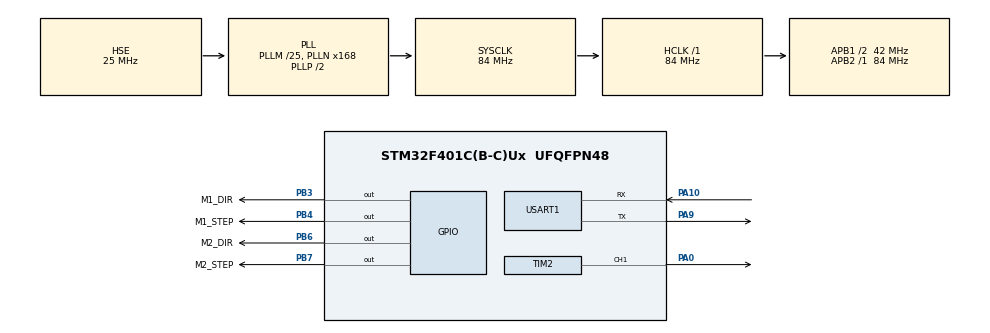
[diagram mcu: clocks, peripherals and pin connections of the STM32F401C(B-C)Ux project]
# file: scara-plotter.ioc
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Mcu.Family=STM32F4
Mcu.Name=STM32F401C(B-C)Ux
Mcu.Package=UFQFPN48
NVIC.PriorityGroup=NVIC_PRIORITYGROUP_4
NVIC.TIM2_IRQn=true\:0\:0\:false\:false\:true\:true\:true
NVIC.USART1_IRQn=true\:0\:0\:false\:false\:true\:true\:true
PA0-WKUP.Signal=S_TIM2_CH1_ETR
PA10.Mode=Asynchronous
PA10.Signal=USART1_RX
PA13.Mode=Serial_Wire
PA13.Signal=SYS_JTMS-SWDIO
PA14.Mode=Serial_Wire
PA14.Signal=SYS_JTCK-SWCLK
PA9.Mode=Asynchronous
PA9.Signal=USART1_TX
PB3.GPIO_Label=M1_DIR
PB3.Signal=GPIO_Output
PB4.GPIO_Label=M1_STEP
PB4.Signal=GPIO_Output
PB6.GPIO_Label=M2_DIR
PB6.Signal=GPIO_Output
PB7.GPIO_Label=M2_STEP
PB7.Signal=GPIO_Output
PH0\ -\ OSC_IN.Mode=HSE-External-Oscillator
PH0\ -\ OSC_IN.Signal=RCC_OSC_IN
PH1\ -\ OSC_OUT.Mode=HSE-External-Oscillator
PH1\ -\ OSC_OUT.Signal=RCC_OSC_OUT
ProjectManager.HeapSize=0x200
ProjectManager.StackSize=0x400
ProjectManager.TargetToolchain=STM32CubeIDE
RCC.48MHZClocksFreq_Value=42000000
RCC.AHBFreq_Value=84000000
RCC.APB1CLKDivider=RCC_HCLK_DIV2
RCC.APB1Freq_Value=42000000
RCC.APB1TimFreq_Value=84000000
RCC.APB2Freq_Value=84000000
RCC.APB2TimFreq_Value=84000000
RCC.CortexFreq_Value=84000000
RCC.HCLKFreq_Value=84000000
RCC.HSE_VALUE=25000000
RCC.HSI_VALUE=16000000
RCC.LSE_VALUE=32768
RCC.PLLM=25
RCC.PLLN=168
RCC.PLLSourceVirtual=RCC_PLLSOURCE_HSE
RCC.SYSCLKFreq_VALUE=84000000
RCC.SYSCLKSource=RCC_SYSCLKSOURCE_PLLCLK
RCC.VCOOutputFreq_Value=168000000
SH.S_TIM2_CH1_ETR.0=TIM2_CH1,PWM Generation1 CH1
TIM2.Channel-PWM\ Generation1\ CH1=TIM_CHANNEL_1
TIM2.Period=59999
TIM2.Prescaler=27
TIM3.Prescaler=83
USART1.VirtualMode=VM_ASYNC
VP_TIM2_VS_ClockSourceINT.Mode=Internal
VP_TIM3_VS_ClockSourceINT.Mode=Internal
board=custom

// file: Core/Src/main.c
/* USER CODE BEGIN Header */
/**
  ******************************************************************************
  * @file           : main.c
  * @brief          : Main program body
  ******************************************************************************
  * @attention
  *
  * <h2><center>&copy; Copyright (c) 2021 STMicroelectronics.
  * All rights reserved.</center></h2>
  *
  * This software component is licensed by ST under BSD 3-Clause license,
  * the "License"; You may not use this file except in compliance with the
  * License. You may obtain a copy of the License at:
  *                        opensource.org/licenses/BSD-3-Clause
  *
  ******************************************************************************
  */
/* USER CODE END Header */
#include "main.h"

TIM_HandleTypeDef htim2;
TIM_HandleTypeDef htim3;

UART_HandleTypeDef huart1;

/* USER CODE BEGIN PV */
TIM_HandleTypeDef *htim = &htim2;
TIM_HandleTypeDef *htim_ms = &htim3;

/* USER CODE END PV */

void SystemClock_Config(void);
static void MX_GPIO_Init(void);
static void MX_TIM2_Init(void);
static void MX_TIM3_Init(void);
static void MX_USART1_UART_Init(void);

int main(void)
{
  /* USER CODE BEGIN 1 */
  uint8_t uart_buffer[40] = {0};

  /* USER CODE END 1 */

  /* MCU Configuration--------------------------------------------------------*/

  /* Reset of all peripherals, Initializes the Flash interface and the Systick. */
  HAL_Init();

  /* Configure the system clock */
  SystemClock_Config();

  /* Initialize all configured peripherals */
  MX_GPIO_Init();
  MX_TIM2_Init();
  MX_TIM3_Init();
  MX_USART1_UART_Init();
  /* USER CODE BEGIN 2 */

  HAL_TIM_PWM_Start(&htim2, TIM_CHANNEL_1);
  HAL_TIM_Base_Start(&htim3);

  lift();
  go_to(0, 200);

  /* USER CODE END 2 */

  /* Infinite loop */
  /* USER CODE BEGIN WHILE */
  while (1)
  {

    HAL_UART_Receive (&huart1, uart_buffer, sizeof(uart_buffer), HAL_MAX_DELAY);

    //procesar
    parse_line(uart_buffer, sizeof(uart_buffer));

    HAL_UART_Transmit(&huart1, "OK\n", 3, HAL_MAX_DELAY);

    //lift();

    //HAL_Delay(1000);

    //go_to(0, 230);
    //put_down();

    //HAL_Delay(1000);

    //go_to(0, 270);

    /*draw_line(-75.0, 250.0, 175.0, 250.0, true);
    draw_line(175.0, 250.0, 175.0, 380.0, true);
    draw_line(175.0, 380.0, -75.0, 380.0, true);
    draw_line(-75.0, 380.0, -75.0, 250.0, false);

    draw_line(-50.0, 275.0, 150.0, 275.0, true);
    draw_line(150.0, 275.0, 150.0, 355.0, true);
    draw_line(150.0, 355.0, -50.0, 355.0, true);
    draw_line(-50.0, 355.0, -50.0, 275.0, false);

    draw_line(-25.0, 300.0, 125.0, 300.0, true);
    draw_line(125.0, 300.0, 125.0, 320.0, true);
    draw_line(125.0, 320.0, -25.0, 320.0, true);
    draw_line(-25.0, 320.0, -25.0, 300.0, false);

    draw_circle(50.0, 315.0, 60.0);
    draw_circle(50.0, 315.0, 50.0);
    draw_circle(50.0, 315.0, 40.0);

    HAL_Delay(30000);*/

    /* USER CODE END WHILE */

  }
}

void SystemClock_Config(void)
{
  RCC_OscInitTypeDef RCC_OscInitStruct = {0};
  RCC_ClkInitTypeDef RCC_ClkInitStruct = {0};

  /** Configure the main internal regulator output voltage
  */
  __HAL_RCC_PWR_CLK_ENABLE();
  __HAL_PWR_VOLTAGESCALING_CONFIG(PWR_REGULATOR_VOLTAGE_SCALE2);
  /** Initializes the RCC Oscillators according to the specified parameters
  * in the RCC_OscInitTypeDef structure.
  */
  RCC_OscInitStruct.OscillatorType = RCC_OSCILLATORTYPE_HSE;
  RCC_OscInitStruct.HSEState = RCC_HSE_ON;
  RCC_OscInitStruct.PLL.PLLState = RCC_PLL_ON;
  RCC_OscInitStruct.PLL.PLLSource = RCC_PLLSOURCE_HSE;
  RCC_OscInitStruct.PLL.PLLM = 25;
  RCC_OscInitStruct.PLL.PLLN = 168;
  RCC_OscInitStruct.PLL.PLLP = RCC_PLLP_DIV2;
  RCC_OscInitStruct.PLL.PLLQ = 4;
  if (HAL_RCC_OscConfig(&RCC_OscInitStruct) != HAL_OK)
  {
    Error_Handler();
  }
  /** Initializes the CPU, AHB and APB buses clocks
  */
  RCC_ClkInitStruct.ClockType = RCC_CLOCKTYPE_HCLK|RCC_CLOCKTYPE_SYSCLK
                              |RCC_CLOCKTYPE_PCLK1|RCC_CLOCKTYPE_PCLK2;
  RCC_ClkInitStruct.SYSCLKSource = RCC_SYSCLKSOURCE_PLLCLK;
  RCC_ClkInitStruct.AHBCLKDivider = RCC_SYSCLK_DIV1;
  RCC_ClkInitStruct.APB1CLKDivider = RCC_HCLK_DIV2;
  RCC_ClkInitStruct.APB2CLKDivider = RCC_HCLK_DIV1;

  if (HAL_RCC_ClockConfig(&RCC_ClkInitStruct, FLASH_LATENCY_2) != HAL_OK)
  {
    Error_Handler();
  }
}

static void MX_TIM2_Init(void)
{

  TIM_ClockConfigTypeDef sClockSourceConfig = {0};
  TIM_MasterConfigTypeDef sMasterConfig = {0};
  TIM_OC_InitTypeDef sConfigOC = {0};

  htim2.Instance = TIM2;
  htim2.Init.Prescaler = 27;
  htim2.Init.CounterMode = TIM_COUNTERMODE_UP;
  htim2.Init.Period = 59999;
  htim2.Init.ClockDivision = TIM_CLOCKDIVISION_DIV1;
  htim2.Init.AutoReloadPreload = TIM_AUTORELOAD_PRELOAD_DISABLE;
  if (HAL_TIM_Base_Init(&htim2) != HAL_OK)
  {
    Error_Handler();
  }
  sClockSourceConfig.ClockSource = TIM_CLOCKSOURCE_INTERNAL;
  if (HAL_TIM_ConfigClockSource(&htim2, &sClockSourceConfig) != HAL_OK)
  {
    Error_Handler();
  }
  if (HAL_TIM_PWM_Init(&htim2) != HAL_OK)
  {
    Error_Handler();
  }
  sMasterConfig.MasterOutputTrigger = TIM_TRGO_RESET;
  sMasterConfig.MasterSlaveMode = TIM_MASTERSLAVEMODE_DISABLE;
  if (HAL_TIMEx_MasterConfigSynchronization(&htim2, &sMasterConfig) != HAL_OK)
  {
    Error_Handler();
  }
  sConfigOC.OCMode = TIM_OCMODE_PWM1;
  sConfigOC.Pulse = 0;
  sConfigOC.OCPolarity = TIM_OCPOLARITY_HIGH;
  sConfigOC.OCFastMode = TIM_OCFAST_DISABLE;
  if (HAL_TIM_PWM_ConfigChannel(&htim2, &sConfigOC, TIM_CHANNEL_1) != HAL_OK)
  {
    Error_Handler();
  }
  HAL_TIM_MspPostInit(&htim2);

}

static void MX_TIM3_Init(void)
{

  TIM_ClockConfigTypeDef sClockSourceConfig = {0};
  TIM_MasterConfigTypeDef sMasterConfig = {0};

  htim3.Instance = TIM3;
  htim3.Init.Prescaler = 83;
  htim3.Init.CounterMode = TIM_COUNTERMODE_UP;
  htim3.Init.Period = 65535;
  htim3.Init.ClockDivision = TIM_CLOCKDIVISION_DIV1;
  htim3.Init.AutoReloadPreload = TIM_AUTORELOAD_PRELOAD_DISABLE;
  if (HAL_TIM_Base_Init(&htim3) != HAL_OK)
  {
    Error_Handler();
  }
  sClockSourceConfig.ClockSource = TIM_CLOCKSOURCE_INTERNAL;
  if (HAL_TIM_ConfigClockSource(&htim3, &sClockSourceConfig) != HAL_OK)
  {
    Error_Handler();
  }
  sMasterConfig.MasterOutputTrigger = TIM_TRGO_RESET;
  sMasterConfig.MasterSlaveMode = TIM_MASTERSLAVEMODE_DISABLE;
  if (HAL_TIMEx_MasterConfigSynchronization(&htim3, &sMasterConfig) != HAL_OK)
  {
    Error_Handler();
  }

}

static void MX_USART1_UART_Init(void)
{

  huart1.Instance = USART1;
  huart1.Init.BaudRate = 115200;
  huart1.Init.WordLength = UART_WORDLENGTH_8B;
  huart1.Init.StopBits = UART_STOPBITS_1;
  huart1.Init.Parity = UART_PARITY_NONE;
  huart1.Init.Mode = UART_MODE_TX_RX;
  huart1.Init.HwFlowCtl = UART_HWCONTROL_NONE;
  huart1.Init.OverSampling = UART_OVERSAMPLING_16;
  if (HAL_UART_Init(&huart1) != HAL_OK)
  {
    Error_Handler();
  }

}

static void MX_GPIO_Init(void)
{
  GPIO_InitTypeDef GPIO_InitStruct = {0};

  /* GPIO Ports Clock Enable */
  __HAL_RCC_GPIOH_CLK_ENABLE();
  __HAL_RCC_GPIOA_CLK_ENABLE();
  __HAL_RCC_GPIOB_CLK_ENABLE();

  /*Configure GPIO pin Output Level */
  HAL_GPIO_WritePin(GPIOB, M1_DIR_Pin|M1_STEP_Pin|M2_DIR_Pin|M2_STEP_Pin, GPIO_PIN_RESET);

  /*Configure GPIO pins : M1_DIR_Pin M1_STEP_Pin M2_DIR_Pin M2_STEP_Pin */
  GPIO_InitStruct.Pin = M1_DIR_Pin|M1_STEP_Pin|M2_DIR_Pin|M2_STEP_Pin;
  GPIO_InitStruct.Mode = GPIO_MODE_OUTPUT_PP;
  GPIO_InitStruct.Pull = GPIO_NOPULL;
  GPIO_InitStruct.Speed = GPIO_SPEED_FREQ_LOW;
  HAL_GPIO_Init(GPIOB, &GPIO_InitStruct);

}

void Error_Handler(void)
{
}

/************************ (C) COPYRIGHT STMicroelectronics *****END OF FILE****/
